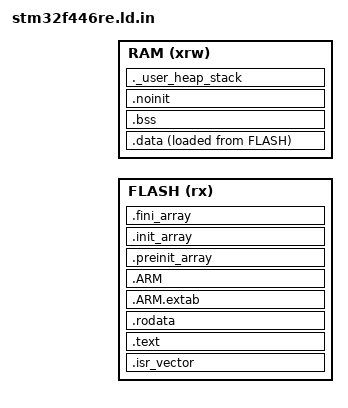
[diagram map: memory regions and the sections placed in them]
/*
 * Linker script template for STM32F446RE.
 *
 * This file is preprocessed by arm-none-eabi-gcc during pre-build to produce
 * ldscripts/stm32f446re.ld. Memory layout constants are sourced from
 * config/stm32f446re/memory_map.h — edit that file to retarget.
 *
 * Do NOT edit ldscripts/stm32f446re.ld directly; it is a generated artifact.
 */

#define LINKER_SCRIPT
#include "memory_map.h"

/* Entry Point */
ENTRY(Reset_Handler)

/* Initial stack pointer — top of SRAM */
_estack = MAIN_STACK_START;

/* Minimum reserved stack and heap regions (linker-enforced RAM check) */
_Min_Heap_Size  = RTOS_MIN_HEAP_SIZE;
_Min_Stack_Size = MAIN_STACK_SIZE;

/* Memory regions */
MEMORY
{
  FLASH (rx)  : ORIGIN = FLASH_BASE_ADDR, LENGTH = FLASH_SIZE
  RAM   (xrw) : ORIGIN = SRAM_BASE_ADDR,  LENGTH = SRAM_SIZE
}

/* Output sections */
SECTIONS
{
  /* Interrupt vector table — must be first in FLASH */
  .isr_vector :
  {
    . = ALIGN(4);
    KEEP(*(.isr_vector))
    . = ALIGN(4);
  } >FLASH

  /* Program code and read-only data */
  .text :
  {
    . = ALIGN(4);
    *(.text)
    *(.text*)
    *(.glue_7)
    *(.glue_7t)
    *(.eh_frame)

    KEEP (*(.init))
    KEEP (*(.fini))

    . = ALIGN(4);
    _etext = .;
  } >FLASH

  .rodata :
  {
    . = ALIGN(4);
    *(.rodata)
    *(.rodata*)
    . = ALIGN(4);
  } >FLASH

  .ARM.extab :
  {
    . = ALIGN(4);
    *(.ARM.extab* .gnu.linkonce.armextab.*)
    . = ALIGN(4);
  } >FLASH

  .ARM :
  {
    . = ALIGN(4);
    __exidx_start = .;
    *(.ARM.exidx*)
    __exidx_end = .;
    . = ALIGN(4);
  } >FLASH

  .preinit_array :
  {
    . = ALIGN(4);
    PROVIDE_HIDDEN (__preinit_array_start = .);
    KEEP (*(.preinit_array*))
    PROVIDE_HIDDEN (__preinit_array_end = .);
    . = ALIGN(4);
  } >FLASH

  .init_array :
  {
    . = ALIGN(4);
    PROVIDE_HIDDEN (__init_array_start = .);
    KEEP (*(SORT(.init_array.*)))
    KEEP (*(.init_array*))
    PROVIDE_HIDDEN (__init_array_end = .);
    . = ALIGN(4);
  } >FLASH

  .fini_array :
  {
    . = ALIGN(4);
    PROVIDE_HIDDEN (__fini_array_start = .);
    KEEP (*(SORT(.fini_array.*)))
    KEEP (*(.fini_array*))
    PROVIDE_HIDDEN (__fini_array_end = .);
    . = ALIGN(4);
  } >FLASH

  /* Load address of .data in FLASH, copied to RAM by startup code */
  _sidata = LOADADDR(.data);

  /* Initialised data — loaded from FLASH, executed from RAM */
  .data :
  {
    . = ALIGN(4);
    _sdata = .;
    *(.data)
    *(.data*)
    *(.RamFunc)
    *(.RamFunc*)
    . = ALIGN(4);
    _edata = .;
  } >RAM AT> FLASH

  /* Uninitialised data — zeroed by startup code */
  . = ALIGN(4);
  .bss :
  {
    _sbss = .;
    __bss_start__ = _sbss;
    *(.bss)
    *(.bss*)
    *(COMMON)
    . = ALIGN(4);
    _ebss = .;
    __bss_end__ = _ebss;
  } >RAM

  /* Not initialised by startup code — survives NVIC_SystemReset() */
  . = ALIGN(4);
  .noinit (NOLOAD) :
  {
    . = ALIGN(4);
    *(.noinit)
    *(.noinit*)
    . = ALIGN(4);
  } >RAM

  /* Heap + stack reservation — linker errors here mean RAM is exhausted */
  ._user_heap_stack :
  {
    . = ALIGN(8);
    PROVIDE ( end = . );
    PROVIDE ( _end = . );
    . = . + _Min_Heap_Size;
    . = . + _Min_Stack_Size;
    . = ALIGN(8);
  } >RAM

  /DISCARD/ :
  {
    libc.a ( * )
    libm.a ( * )
    libgcc.a ( * )
  }

  .ARM.attributes 0 : { *(.ARM.attributes) }
}
